AUTOSAR XML (schema 4-0-3)
standard types defined: UInt32, UInt8
package /AUTOSAR_Platform/DataConstrs
  range DC_UInt8: raw 0..255
package /PATAC/MSM/ComponentTypes
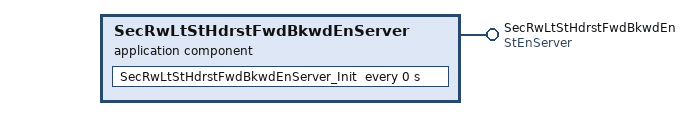
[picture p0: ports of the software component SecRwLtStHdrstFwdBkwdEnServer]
  application sw component type SecRwLtStHdrstFwdBkwdEnServer
    provide port SecRwLtStHdrstFwdBkwdEn: provided-com-specs=[{operation=Clear, queue-length=1}, {operation=Get, queue-length=1}, {operation=Set, queue-length=1}], provided-interface=StEnServer
    behavior SecRwLtStHdrstFwdBkwdEnServer_InternalBehavior
      operation invoked event OIT_SecRwLtStHdrstFwdBkwdEn_Clear_SecRwLtStHdrstFwdBkwdEn_Clear: start-on-event=SecRwLtStHdrstFwdBkwdEn_Clear, operation=SecRwLtStHdrstFwdBkwdEn.Clear
      operation invoked event OIT_SecRwLtStHdrstFwdBkwdEn_Get_SecRwLtStHdrstFwdBkwdEn_Get: start-on-event=SecRwLtStHdrstFwdBkwdEn_Get, operation=SecRwLtStHdrstFwdBkwdEn.Get
      operation invoked event OIT_SecRwLtStHdrstFwdBkwdEn_Set_SecRwLtStHdrstFwdBkwdEn_Set: start-on-event=SecRwLtStHdrstFwdBkwdEn_Set, operation=SecRwLtStHdrstFwdBkwdEn.Set
      timing event SecRwLtStHdrstFwdBkwdEnServer_InitEvent: start-on-event=SecRwLtStHdrstFwdBkwdEnServer_Init, period=0
      4 x runnable:
        SecRwLtStHdrstFwdBkwdEn_Clear
        SecRwLtStHdrstFwdBkwdEn_Get
        SecRwLtStHdrstFwdBkwdEn_Set
        SecRwLtStHdrstFwdBkwdEnServer_Init
  swc implementation SecRwLtStHdrstFwdBkwdEnServer_Implementation: behavior=SecRwLtStHdrstFwdBkwdEnServer_InternalBehavior
    code-descriptors:
      code Default: artifact-descriptors=autosar-engineering-object={short-label=Default, category=SWSRC}
package /PATAC/MSM/ModeAdjust/PortInterface
  client server interface StEnServer
    operation Clear
      arg data: type=UInt8, direction=IN, server-argument-impl-policy=USE-ARGUMENT-TYPE
    operation Get
      arg data: type=UInt32, direction=OUT, server-argument-impl-policy=USE-ARGUMENT-TYPE
    operation Set
      arg data: type=UInt8, direction=IN, server-argument-impl-policy=USE-ARGUMENT-TYPE
